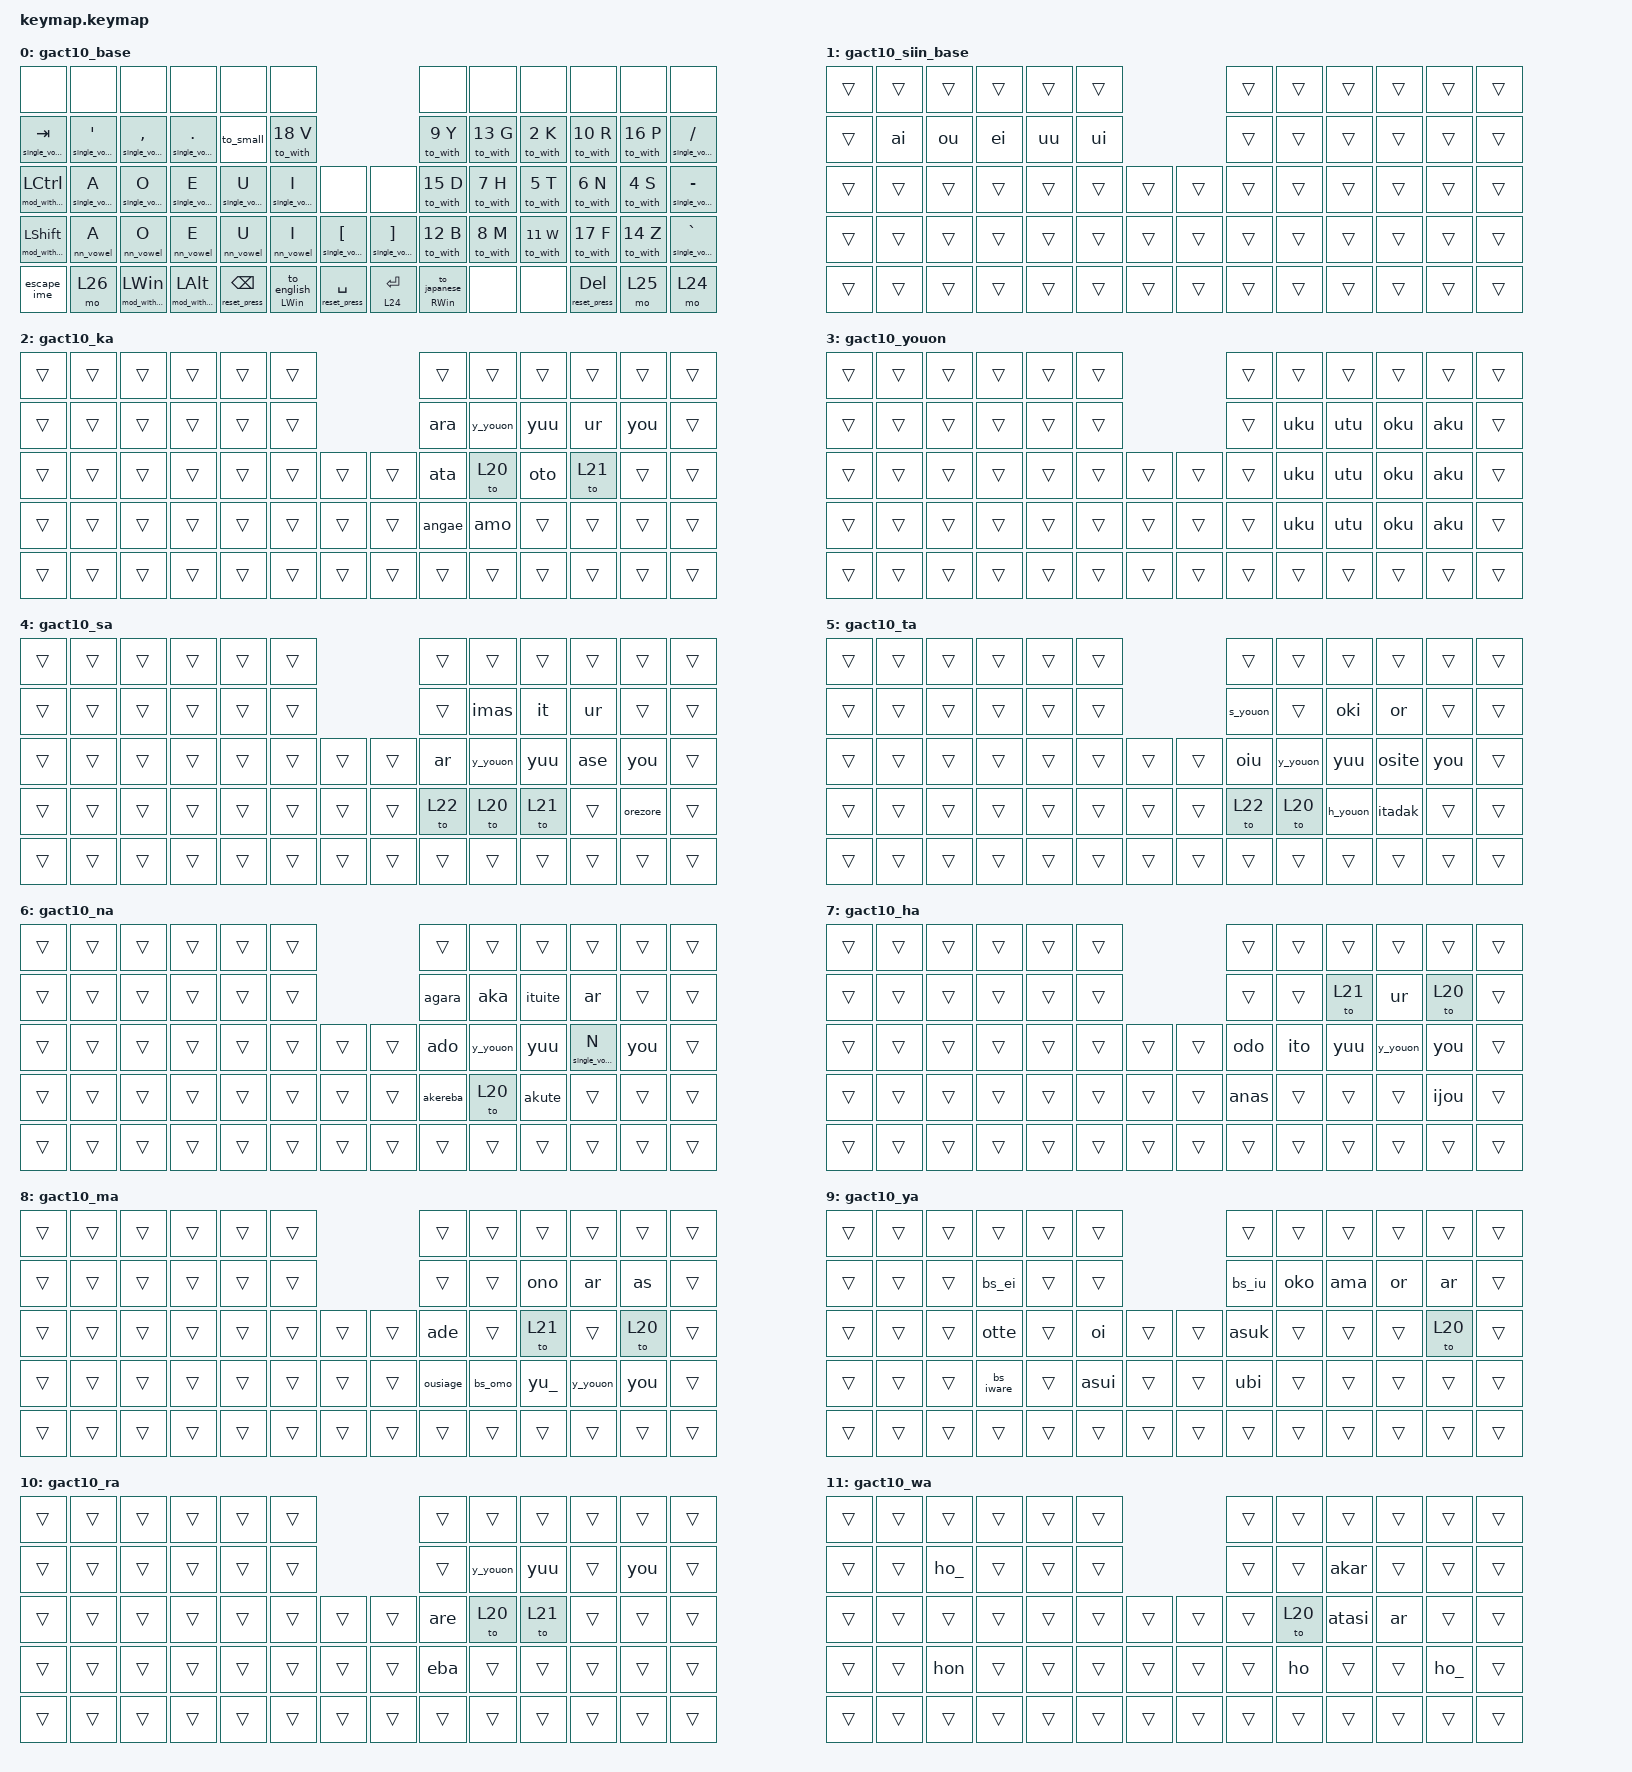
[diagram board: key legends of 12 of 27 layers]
#include <behaviors.dtsi>
#include <dt-bindings/zmk/bt.h>
#include <dt-bindings/zmk/keys.h>
#include <dt-bindings/zmk/outputs.h>
#include <dt-bindings/zmk/pointing.h>

/ {
    combos {
        compatible = "zmk,combos";

        lpar {
            bindings = <&kp LPAR>;
            key-positions = <28 16>;
        };

        rpar {
            bindings = <&kp RPAR>;
            key-positions = <17 29>;
        };
    };

    macros {
        to_small: small {
            compatible = "zmk,behavior-macro";
            #binding-cells = <0>;
            bindings = <&to 0 &tog 19 &kp X &kp T &kp U>;
            label = "SMALL";
            wait-ms = <0>;
            tap-ms = <0>;
        };

        ai: ai {
            compatible = "zmk,behavior-macro";
            #binding-cells = <0>;
            bindings = <&to 0 &kp A &kp I>;
            label = "AI";
            wait-ms = <0>;
            tap-ms = <0>;
        };

        ou: ou {
            compatible = "zmk,behavior-macro";
            #binding-cells = <0>;
            bindings = <&to 0 &kp O &kp U>;
            label = "OU";
            wait-ms = <0>;
            tap-ms = <0>;
        };

        ei: ei {
            compatible = "zmk,behavior-macro";
            #binding-cells = <0>;
            bindings = <&to 0 &kp E &kp I>;
            label = "EI";
            wait-ms = <0>;
            tap-ms = <0>;
        };

        uu: uu {
            compatible = "zmk,behavior-macro";
            #binding-cells = <0>;
            bindings = <&to 0 &kp U &kp U>;
            label = "UU";
            wait-ms = <0>;
            tap-ms = <0>;
        };

        ui: ui {
            compatible = "zmk,behavior-macro";
            #binding-cells = <0>;
            bindings = <&to 0 &kp U &kp I>;
            label = "UI";
            wait-ms = <0>;
            tap-ms = <0>;
        };

        ara: ara {
            compatible = "zmk,behavior-macro";
            #binding-cells = <0>;
            bindings = <&to 0 &kp A &kp R &kp A>;
            label = "ARA";
            wait-ms = <0>;
            tap-ms = <0>;
        };

        ata: ata {
            compatible = "zmk,behavior-macro";
            #binding-cells = <0>;
            bindings = <&to 0 &kp A &kp T &kp A>;
            label = "ATA";
            wait-ms = <0>;
            tap-ms = <0>;
        };

        angae: angae {
            compatible = "zmk,behavior-macro";
            #binding-cells = <0>;
            bindings = <&to 0 &kp A &kp N &kp G &kp A &kp E>;
            label = "ANGAE";
            wait-ms = <0>;
            tap-ms = <0>;
        };

        amo: amo {
            compatible = "zmk,behavior-macro";
            #binding-cells = <0>;
            bindings = <&to 0 &kp A &kp M &kp O>;
            label = "AMO";
            wait-ms = <0>;
            tap-ms = <0>;
        };

        y_youon: y_youon {
            compatible = "zmk,behavior-macro";
            #binding-cells = <0>;
            bindings = <&to 0 &tog 1 &tog 3 &kp Y>;
            label = "Y_YOUON";
            wait-ms = <0>;
            tap-ms = <0>;
        };

        oto: oto {
            compatible = "zmk,behavior-macro";
            #binding-cells = <0>;
            bindings = <&to 0 &kp O &kp T &kp O>;
            label = "OTO";
            wait-ms = <0>;
            tap-ms = <0>;
        };

        yuu: yuu {
            compatible = "zmk,behavior-macro";
            #binding-cells = <0>;
            bindings = <&to 0 &kp Y &kp U &kp U>;
            label = "YUU";
            wait-ms = <0>;
            tap-ms = <0>;
        };

        you: you {
            compatible = "zmk,behavior-macro";
            #binding-cells = <0>;
            bindings = <&to 0 &kp Y &kp O &kp U>;
            label = "YOU";
            wait-ms = <0>;
            tap-ms = <0>;
        };

        ur: ur {
            compatible = "zmk,behavior-macro";
            #binding-cells = <0>;
            bindings = <&to 0 &tog 1 &tog 10 &kp U &kp R>;
            label = "UR";
            wait-ms = <0>;
            tap-ms = <0>;
        };

        uku: uku {
            compatible = "zmk,behavior-macro";
            #binding-cells = <0>;
            bindings = <&to 0 &kp U &kp K &kp U>;
            label = "UKU";
            wait-ms = <0>;
            tap-ms = <0>;
        };

        utu: utu {
            compatible = "zmk,behavior-macro";
            #binding-cells = <0>;
            bindings = <&to 0 &kp U &kp T &kp U>;
            label = "UTU";
            wait-ms = <0>;
            tap-ms = <0>;
        };

        oku: otu {
            compatible = "zmk,behavior-macro";
            #binding-cells = <0>;
            bindings = <&to 0 &kp O &kp K &kp U>;
            label = "OTU";
            wait-ms = <0>;
            tap-ms = <0>;
        };

        aku: aku {
            compatible = "zmk,behavior-macro";
            #binding-cells = <0>;
            bindings = <&to 0 &kp A &kp K &kp U>;
            label = "AKU";
            wait-ms = <0>;
            tap-ms = <0>;
        };

        ar: ar {
            compatible = "zmk,behavior-macro";
            #binding-cells = <0>;
            bindings = <&to 0 &tog 1 &tog 10 &kp A &kp R>;
            label = "AR";
            wait-ms = <0>;
            tap-ms = <0>;
        };

        imas: imas {
            compatible = "zmk,behavior-macro";
            #binding-cells = <0>;
            bindings = <&to 0 &tog 1 &to 4 &kp I &kp M &kp A &kp S>;
            label = "IMAS";
            wait-ms = <0>;
            tap-ms = <0>;
        };

        it: it {
            compatible = "zmk,behavior-macro";
            #binding-cells = <0>;
            bindings = <&to 0 &tog 1 &tog 5 &kp I &kp T>;
            label = "IT";
            wait-ms = <0>;
            tap-ms = <0>;
        };

        orezore: orezore {
            compatible = "zmk,behavior-macro";
            #binding-cells = <0>;
            bindings = <&to 0 &kp O &kp R &kp E &kp Z &kp O &kp R &kp E>;
            label = "OREZORE";
            wait-ms = <0>;
            tap-ms = <0>;
        };

        ase: ase {
            compatible = "zmk,behavior-macro";
            #binding-cells = <0>;
            bindings = <&to 0 &kp A &kp S &kp E>;
            label = "ASE";
            wait-ms = <0>;
            tap-ms = <0>;
        };

        s_youon: s_youon {
            compatible = "zmk,behavior-macro";
            #binding-cells = <0>;
            bindings = <&to 0 &tog 1 &to 3 &kp S>;
            label = "S_YOUON";
            wait-ms = <0>;
            tap-ms = <0>;
        };

        oiu: oiu {
            compatible = "zmk,behavior-macro";
            #binding-cells = <0>;
            bindings = <&to 0 &kp O &kp I &kp U>;
            label = "OIU";
            wait-ms = <0>;
            tap-ms = <0>;
        };

        oki: oki {
            compatible = "zmk,behavior-macro";
            #binding-cells = <0>;
            bindings = <&to 0 &kp O &kp K &kp I>;
            label = "OKI";
            wait-ms = <0>;
            tap-ms = <0>;
        };

        osite: osite {
            compatible = "zmk,behavior-macro";
            #binding-cells = <0>;
            bindings = <&to 0 &kp O &kp S &kp I &kp T &kp E>;
            label = "OSITE";
            wait-ms = <0>;
            tap-ms = <0>;
        };

        or: or {
            compatible = "zmk,behavior-macro";
            #binding-cells = <0>;
            bindings = <&to 0 &tog 1 &tog 10 &kp O &kp R>;
            label = "OR";
            wait-ms = <0>;
            tap-ms = <0>;
        };

        itadak: itadak {
            compatible = "zmk,behavior-macro";
            #binding-cells = <0>;
            bindings = <&to 0 &tog 1 &tog 2 &kp BACKSPACE &kp I &kp T &kp A &kp D &kp A &kp K>;
            label = "ITADAK";
            wait-ms = <0>;
            tap-ms = <0>;
        };

        h_youon: h_youon {
            compatible = "zmk,behavior-macro";
            #binding-cells = <0>;
            bindings = <&to 0 &tog 1 &tog 3 &kp H>;
            label = "H_YOUON";
            wait-ms = <0>;
            tap-ms = <0>;
        };

        agara: agara {
            compatible = "zmk,behavior-macro";
            #binding-cells = <0>;
            bindings = <&to 0 &kp A &kp G &kp A &kp R &kp A>;
            label = "AGARA";
            wait-ms = <0>;
            tap-ms = <0>;
        };

        ado: ado {
            compatible = "zmk,behavior-macro";
            #binding-cells = <0>;
            bindings = <&to 0 &kp A &kp D &kp O>;
            label = "ADO";
            wait-ms = <0>;
            tap-ms = <0>;
        };

        akereba: akereba {
            compatible = "zmk,behavior-macro";
            #binding-cells = <0>;
            bindings = <&to 0 &kp A &kp K &kp E &kp R &kp E &kp B &kp A>;
            label = "AKEREBA";
            wait-ms = <0>;
            tap-ms = <0>;
        };

        aka: aka {
            compatible = "zmk,behavior-macro";
            #binding-cells = <0>;
            bindings = <&to 0 &kp A &kp K &kp A>;
            label = "AKA";
            wait-ms = <0>;
            tap-ms = <0>;
        };

        ituite: ituite {
            compatible = "zmk,behavior-macro";
            #binding-cells = <0>;
            bindings = <&to 0 &kp I &kp T &kp U &kp I &kp T &kp E>;
            label = "ITUITE";
            wait-ms = <0>;
            tap-ms = <0>;
        };

        akute: akute {
            compatible = "zmk,behavior-macro";
            #binding-cells = <0>;
            bindings = <&to 0 &kp A &kp K &kp U &kp T &kp E>;
            label = "AKUTE";
            wait-ms = <0>;
            tap-ms = <0>;
        };

        odo: odo {
            compatible = "zmk,behavior-macro";
            #binding-cells = <0>;
            bindings = <&to 0 &kp O &kp D &kp O>;
            label = "ODO";
            wait-ms = <0>;
            tap-ms = <0>;
        };

        anas: anas {
            compatible = "zmk,behavior-macro";
            #binding-cells = <0>;
            bindings = <&to 0 &tog 1 &tog 4 &kp A &kp N &kp A &kp S>;
            label = "ANAS";
            wait-ms = <0>;
            tap-ms = <0>;
        };

        ito: ito {
            compatible = "zmk,behavior-macro";
            #binding-cells = <0>;
            bindings = <&to 0 &kp I &kp T &kp O>;
            label = "ITO";
            wait-ms = <0>;
            tap-ms = <0>;
        };

        ijou: ijou {
            compatible = "zmk,behavior-macro";
            #binding-cells = <0>;
            bindings = <&to 0 &kp I &kp J &kp O &kp U>;
            label = "IJOU";
            wait-ms = <0>;
            tap-ms = <0>;
        };

        ade: ade {
            compatible = "zmk,behavior-macro";
            #binding-cells = <0>;
            bindings = <&to 0 &kp A &kp D &kp E>;
            label = "ADE";
            wait-ms = <0>;
            tap-ms = <0>;
        };

        ousiage: ousiage {
            compatible = "zmk,behavior-macro";
            #binding-cells = <0>;
            bindings = <&to 0 &kp O &kp U &kp S &kp I &kp A &kp G &kp E>;
            label = "OUSIAGE";
            wait-ms = <0>;
            tap-ms = <0>;
        };

        bs_omo: omo {
            compatible = "zmk,behavior-macro";
            #binding-cells = <0>;
            bindings = <&to 0 &kp BACKSPACE &kp O &kp M &kp O>;
            label = "OMO";
            wait-ms = <0>;
            tap-ms = <0>;
        };

        ono: ono {
            compatible = "zmk,behavior-macro";
            #binding-cells = <0>;
            bindings = <&to 0 &kp O &kp N &kp O>;
            label = "ONO";
            wait-ms = <0>;
            tap-ms = <0>;
        };

        yu_: yu_ {
            compatible = "zmk,behavior-macro";
            #binding-cells = <0>;
            bindings = <&to 0 &kp Y &kp U &kp MINUS>;
            label = "YU_";
            wait-ms = <0>;
            tap-ms = <0>;
        };

        as: as {
            compatible = "zmk,behavior-macro";
            #binding-cells = <0>;
            bindings = <&to 0 &tog 1 &tog 4 &kp A &kp S>;
            label = "AS";
            wait-ms = <0>;
            tap-ms = <0>;
        };

        otte: otte {
            compatible = "zmk,behavior-macro";
            #binding-cells = <0>;
            bindings = <&to 0 &kp O &kp T &kp T &kp E>;
            label = "OTTE";
            wait-ms = <0>;
            tap-ms = <0>;
        };

        bs_ei: bs_ei {
            compatible = "zmk,behavior-macro";
            #binding-cells = <0>;
            bindings = <&to 0 &kp BACKSPACE &kp E &kp I>;
            label = "BS_EI";
            wait-ms = <0>;
            tap-ms = <0>;
        };

        bs_iware: bs_iware {
            compatible = "zmk,behavior-macro";
            #binding-cells = <0>;
            bindings = <&to 0 &kp BACKSPACE &kp I &kp W &kp A &kp R &kp E>;
            label = "BS_IWARE";
            wait-ms = <0>;
            tap-ms = <0>;
        };

        oi: oi {
            compatible = "zmk,behavior-macro";
            #binding-cells = <0>;
            bindings = <&to 0 &kp O &kp I>;
            label = "OI";
            wait-ms = <0>;
            tap-ms = <0>;
        };

        asui: asui {
            compatible = "zmk,behavior-macro";
            #binding-cells = <0>;
            bindings = <&to 0 &kp A &kp S &kp U &kp I>;
            label = "ASUI";
            wait-ms = <0>;
            tap-ms = <0>;
        };

        bs_iu: bs_iu {
            compatible = "zmk,behavior-macro";
            #binding-cells = <0>;
            bindings = <&to 0 &kp BACKSPACE &kp I &kp U>;
            label = "BS_IU";
            wait-ms = <0>;
            tap-ms = <0>;
        };

        oko: oko {
            compatible = "zmk,behavior-macro";
            #binding-cells = <0>;
            bindings = <&to 0 &kp O &kp K &kp O>;
            label = "OKO";
            wait-ms = <0>;
            tap-ms = <0>;
        };

        ama: ama {
            compatible = "zmk,behavior-macro";
            #binding-cells = <0>;
            bindings = <&to 0 &kp A &kp M &kp A>;
            label = "AMA";
            wait-ms = <0>;
            tap-ms = <0>;
        };

        asuk: asuk {
            compatible = "zmk,behavior-macro";
            #binding-cells = <0>;
            bindings = <&to 0 &tog 1 &tog 2 &kp A &kp S &kp U &kp K>;
            label = "ASUK";
            wait-ms = <0>;
            tap-ms = <0>;
        };

        ubi: ubi {
            compatible = "zmk,behavior-macro";
            #binding-cells = <0>;
            bindings = <&to 0 &kp U &kp B &kp I>;
            label = "UBI";
            wait-ms = <0>;
            tap-ms = <0>;
        };

        are: are {
            compatible = "zmk,behavior-macro";
            #binding-cells = <0>;
            bindings = <&to 0 &kp A &kp R &kp E>;
            label = "ARE";
            wait-ms = <0>;
            tap-ms = <0>;
        };

        eba: eba {
            compatible = "zmk,behavior-macro";
            #binding-cells = <0>;
            bindings = <&to 0 &kp E &kp B &kp A>;
            label = "EBA";
            wait-ms = <0>;
            tap-ms = <0>;
        };

        ho_: ho_ {
            compatible = "zmk,behavior-macro";
            #binding-cells = <0>;
            bindings = <&to 0 &kp H &kp O &kp MINUS>;
            label = "HO_";
            wait-ms = <0>;
            tap-ms = <0>;
        };

        atasi: atasi {
            compatible = "zmk,behavior-macro";
            #binding-cells = <0>;
            bindings = <&to 0 &kp A &kp T &kp A &kp S &kp I>;
            label = "ATASI";
            wait-ms = <0>;
            tap-ms = <0>;
        };

        ho: ho {
            compatible = "zmk,behavior-macro";
            #binding-cells = <0>;
            bindings = <&to 0 &kp H &kp O>;
            label = "HO";
            wait-ms = <0>;
            tap-ms = <0>;
        };

        akar: akar {
            compatible = "zmk,behavior-macro";
            #binding-cells = <0>;
            bindings = <&to 0 &tog 1 &tog 10 &kp A &kp K &kp A &kp R>;
            label = "AKAR";
            wait-ms = <0>;
            tap-ms = <0>;
        };

        hon: hon {
            compatible = "zmk,behavior-macro";
            #binding-cells = <0>;
            bindings = <&to 0 &kp H &kp O &kp N &kp N>;
            label = "HON";
            wait-ms = <0>;
            tap-ms = <0>;
        };

        eki: eki {
            compatible = "zmk,behavior-macro";
            #binding-cells = <0>;
            bindings = <&to 0 &kp E &kp K &kp I>;
            label = "EKI";
            wait-ms = <0>;
            tap-ms = <0>;
        };

        aruwo: aruwo {
            compatible = "zmk,behavior-macro";
            #binding-cells = <0>;
            bindings = <&to 0 &kp A &kp R &kp U &kp W &kp O>;
            label = "ARUWO";
            wait-ms = <0>;
            tap-ms = <0>;
        };

        bs_node: ode {
            compatible = "zmk,behavior-macro";
            #binding-cells = <0>;
            bindings = <&to 0 &kp BACKSPACE &kp N &kp O &kp D &kp E>;
            label = "ODE";
            wait-ms = <0>;
            tap-ms = <0>;
        };

        aga: aga {
            compatible = "zmk,behavior-macro";
            #binding-cells = <0>;
            bindings = <&to 0 &kp A &kp G &kp A>;
            label = "AGA";
            wait-ms = <0>;
            tap-ms = <0>;
        };

        eha: eha {
            compatible = "zmk,behavior-macro";
            #binding-cells = <0>;
            bindings = <&to 0 &kp E &kp H &kp A>;
            label = "EHA";
            wait-ms = <0>;
            tap-ms = <0>;
        };

        emo: emo {
            compatible = "zmk,behavior-macro";
            #binding-cells = <0>;
            bindings = <&to 0 &kp E &kp M &kp O>;
            label = "EMO";
            wait-ms = <0>;
            tap-ms = <0>;
        };

        ear: ear {
            compatible = "zmk,behavior-macro";
            #binding-cells = <0>;
            bindings = <&to 0 &tog 1 &tog 10 &kp E &kp A &kp R>;
            label = "EAR";
            wait-ms = <0>;
            tap-ms = <0>;
        };

        es: es {
            compatible = "zmk,behavior-macro";
            #binding-cells = <0>;
            bindings = <&to 0 &tog 1 &tog 4 &kp E &kp S>;
            label = "ES";
            wait-ms = <0>;
            tap-ms = <0>;
        };

        o_: o_ {
            compatible = "zmk,behavior-macro";
            #binding-cells = <0>;
            bindings = <&to 0 &kp O &kp MINUS>;
            label = "O_";
            wait-ms = <0>;
            tap-ms = <0>;
        };

        bs_onazi: bs_onazi {
            compatible = "zmk,behavior-macro";
            #binding-cells = <0>;
            bindings = <&to 0 &kp BACKSPACE &kp O &kp N &kp A &kp Z &kp I>;
            label = "BS_ONAZI";
            wait-ms = <0>;
            tap-ms = <0>;
        };

        yun: yun {
            compatible = "zmk,behavior-macro";
            #binding-cells = <0>;
            bindings = <&to 0 &kp Y &kp U &kp N &kp N>;
            label = "YUN";
            wait-ms = <0>;
            tap-ms = <0>;
        };

        yu: yu {
            compatible = "zmk,behavior-macro";
            #binding-cells = <0>;
            bindings = <&to 0 &kp Y &kp U>;
            label = "YU";
            wait-ms = <0>;
            tap-ms = <0>;
        };

        x_txx: ta {
            compatible = "zmk,behavior-macro-one-param";
            #binding-cells = <1>;
            bindings = <&to 0 &kp T &macro_param_1to1 &kp MACRO_PLACEHOLDER>;
            label = "TA";
            wait-ms = <0>;
            tap-ms = <0>;
        };

        bs_x_xx: bs_xa {
            compatible = "zmk,behavior-macro-one-param";
            #binding-cells = <1>;
            bindings = <&to 0 &kp BACKSPACE &kp X &macro_param_1to1 &kp MACRO_PLACEHOLDER>;
            label = "BS_XA";
            wait-ms = <0>;
            tap-ms = <0>;
        };

        bs_xwa: bs_xwa {
            compatible = "zmk,behavior-macro";
            #binding-cells = <0>;
            bindings = <&to 0 &kp BACKSPACE &kp X &kp W &kp A>;
            label = "BS_XWA";
            wait-ms = <0>;
            tap-ms = <0>;
        };

        bs_xy: bs_xy {
            compatible = "zmk,behavior-macro";
            #binding-cells = <0>;
            bindings = <&to 0 &to 1 &kp BACKSPACE &kp X &kp Y>;
            label = "BS_XY";
            wait-ms = <0>;
            tap-ms = <0>;
        };

        to_with: to_sa {
            compatible = "zmk,behavior-macro-two-param";
            #binding-cells = <2>;
            bindings = <&to 0 &tog 1 &macro_param_1to1 &tog MACRO_PLACEHOLDER &macro_param_2to1 &kp MACRO_PLACEHOLDER>;
            label = "TO_SA";
            wait-ms = <0>;
            tap-ms = <0>;
        };

        to_japanese: to_japanese {
            compatible = "zmk,behavior-macro";
            #binding-cells = <0>;
            bindings = <&to 0 &kp LANGUAGE_1>;
            label = "TO_JAPANESE";
            wait-ms = <0>;
            tap-ms = <0>;
        };

        to_english: to_english {
            compatible = "zmk,behavior-macro";
            #binding-cells = <0>;
            bindings = <&to 23 &kp LANGUAGE_2>;
            label = "TO_ENGLISH";
            wait-ms = <0>;
            tap-ms = <0>;
        };

        xx_ku: xx_ku {
            compatible = "zmk,behavior-macro-one-param";
            #binding-cells = <1>;
            bindings = <&to 0 &macro_param_1to1 &kp MACRO_PLACEHOLDER &kp K &kp U>;
            label = "XX_KU";
            wait-ms = <0>;
            tap-ms = <0>;
        };

        xx_ki: xx_ki {
            compatible = "zmk,behavior-macro-one-param";
            #binding-cells = <1>;
            bindings = <&to 0 &macro_param_1to1 &kp MACRO_PLACEHOLDER &kp K &kp I>;
            label = "XX_KI";
            wait-ms = <0>;
            tap-ms = <0>;
        };

        xx_tu: xx_tu {
            compatible = "zmk,behavior-macro-one-param";
            #binding-cells = <1>;
            bindings = <&to 0 &macro_param_1to1 &kp MACRO_PLACEHOLDER &kp T &kp U>;
            label = "XX_TU";
            wait-ms = <0>;
            tap-ms = <0>;
        };

        single_vowel: single_vowel {
            compatible = "zmk,behavior-macro-one-param";
            #binding-cells = <1>;
            bindings = <&to 0 &macro_param_1to1 &kp MACRO_PLACEHOLDER>;
            label = "SINGLE_VOWEL";
            wait-ms = <0>;
            tap-ms = <0>;
        };

        nn_vowel: nn_vowel {
            compatible = "zmk,behavior-macro-one-param";
            #binding-cells = <1>;
            bindings = <&to 0 &macro_param_1to1 &kp MACRO_PLACEHOLDER &kp N &kp N>;
            label = "NN_VOWEL";
            wait-ms = <0>;
            tap-ms = <0>;
        };

        escape_ime: escape_ime {
            compatible = "zmk,behavior-macro";
            #binding-cells = <0>;
            bindings = <&kp ESCAPE &kp LANGUAGE_2 &to 23>;
            label = "ESCAPE_IME";
            wait-ms = <0>;
            tap-ms = <0>;
        };

        mod_with_mo: new_macro {
            compatible = "zmk,behavior-macro-one-param";
            #binding-cells = <1>;
            bindings =
                <&macro_press>,
                <&mo 23 &macro_param_1to1 &kp MACRO_PLACEHOLDER>,
                <&macro_pause_for_release>,
                <&macro_release>,
                <&mo 23 &macro_param_1to1 &kp MACRO_PLACEHOLDER>;

            label = "NEW_MACRO";
        };

        reset_press: reset_press {
            compatible = "zmk,behavior-macro-one-param";
            #binding-cells = <1>;
            bindings =
                <&to 0>,
                <&macro_press>,
                <&macro_param_1to1 &kp MACRO_PLACEHOLDER>,
                <&macro_pause_for_release>,
                <&macro_release>,
                <&macro_param_1to1 &kp MACRO_PLACEHOLDER>;

            label = "RESET_PRESS";
        };
    };

    behaviors {
        hold_and_tap_eng: hold_and_tap_eng {
            compatible = "zmk,behavior-hold-tap";
            label = "HOLD_AND_TAP_ENG";
            bindings = <&kp>, <&to_english>;

            #binding-cells = <2>;
            tapping-term-ms = <200>;
        };

        hold_and_tap_ja: hold_and_tap_ja {
            compatible = "zmk,behavior-hold-tap";
            label = "HOLD_AND_TAP_JA";
            bindings = <&kp>, <&to_japanese>;

            #binding-cells = <2>;
            tapping-term-ms = <200>;
        };

        ht_vowel: ht_vowel {
            compatible = "zmk,behavior-hold-tap";
            label = "HT_VOWEL";
            bindings = <&mo>, <&single_vowel>;

            #binding-cells = <2>;
            tapping-term-ms = <200>;
        };
    };

    keymap {
        compatible = "zmk,keymap";

        gact10_base {
            bindings = <
&none                    &none              &none                &none                  &none                   &none                                                                              &none                    &none          &none          &none                &none          &none
&single_vowel TAB        &single_vowel SQT  &single_vowel COMMA  &single_vowel PERIOD   &to_small               &to_with 18 V                                                                      &to_with 9 Y             &to_with 13 G  &to_with 2 K   &to_with 10 R        &to_with 16 P  &single_vowel SLASH
&mod_with_mo LCTRL       &single_vowel A    &single_vowel O      &single_vowel E        &single_vowel U         &single_vowel I           &none                       &none                        &to_with 15 D            &to_with 7 H   &to_with 5 T   &to_with 6 N         &to_with 4 S   &single_vowel MINUS
&mod_with_mo LEFT_SHIFT  &nn_vowel A        &nn_vowel O          &nn_vowel E            &nn_vowel U             &nn_vowel I               &single_vowel LEFT_BRACKET  &single_vowel RIGHT_BRACKET  &to_with 12 B            &to_with 8 M   &to_with 11 W  &to_with 17 F        &to_with 14 Z  &single_vowel GRAVE
&escape_ime              &mo 26             &mod_with_mo LWIN    &mod_with_mo LEFT_ALT  &reset_press BACKSPACE  &hold_and_tap_eng LWIN 0  &reset_press SPACE          &ht_vowel 24 ENTER           &hold_and_tap_ja RWIN 0  &none          &none          &reset_press DELETE  &mo 25         &mo 24
            >;
        };

        gact10_siin_base {
            bindings = <
&trans  &trans  &trans  &trans  &trans  &trans                  &trans  &trans  &trans  &trans  &trans  &trans
&trans  &ai     &ou     &ei     &uu     &ui                     &trans  &trans  &trans  &trans  &trans  &trans
&trans  &trans  &trans  &trans  &trans  &trans  &trans  &trans  &trans  &trans  &trans  &trans  &trans  &trans
&trans  &trans  &trans  &trans  &trans  &trans  &trans  &trans  &trans  &trans  &trans  &trans  &trans  &trans
&trans  &trans  &trans  &trans  &trans  &trans  &trans  &trans  &trans  &trans  &trans  &trans  &trans  &trans
            >;
        };

        gact10_ka {
            bindings = <
&trans  &trans  &trans  &trans  &trans  &trans                  &trans  &trans    &trans  &trans  &trans  &trans
&trans  &trans  &trans  &trans  &trans  &trans                  &ara    &y_youon  &yuu    &ur     &you    &trans
&trans  &trans  &trans  &trans  &trans  &trans  &trans  &trans  &ata    &to 20    &oto    &to 21  &trans  &trans
&trans  &trans  &trans  &trans  &trans  &trans  &trans  &trans  &angae  &amo      &trans  &trans  &trans  &trans
&trans  &trans  &trans  &trans  &trans  &trans  &trans  &trans  &trans  &trans    &trans  &trans  &trans  &trans
            >;
        };

        gact10_youon {
            bindings = <
&trans  &trans  &trans  &trans  &trans  &trans                  &trans  &trans  &trans  &trans  &trans  &trans
&trans  &trans  &trans  &trans  &trans  &trans                  &trans  &uku    &utu    &oku    &aku    &trans
&trans  &trans  &trans  &trans  &trans  &trans  &trans  &trans  &trans  &uku    &utu    &oku    &aku    &trans
&trans  &trans  &trans  &trans  &trans  &trans  &trans  &trans  &trans  &uku    &utu    &oku    &aku    &trans
&trans  &trans  &trans  &trans  &trans  &trans  &trans  &trans  &trans  &trans  &trans  &trans  &trans  &trans
            >;
        };

        gact10_sa {
            bindings = <
&trans  &trans  &trans  &trans  &trans  &trans                  &trans  &trans    &trans  &trans  &trans    &trans
&trans  &trans  &trans  &trans  &trans  &trans                  &trans  &imas     &it     &ur     &trans    &trans
&trans  &trans  &trans  &trans  &trans  &trans  &trans  &trans  &ar     &y_youon  &yuu    &ase    &you      &trans
&trans  &trans  &trans  &trans  &trans  &trans  &trans  &trans  &to 22  &to 20    &to 21  &trans  &orezore  &trans
&trans  &trans  &trans  &trans  &trans  &trans  &trans  &trans  &trans  &trans    &trans  &trans  &trans    &trans
            >;
        };

        gact10_ta {
            bindings = <
&trans  &trans  &trans  &trans  &trans  &trans                  &trans    &trans    &trans    &trans   &trans  &trans
&trans  &trans  &trans  &trans  &trans  &trans                  &s_youon  &trans    &oki      &or      &trans  &trans
&trans  &trans  &trans  &trans  &trans  &trans  &trans  &trans  &oiu      &y_youon  &yuu      &osite   &you    &trans
&trans  &trans  &trans  &trans  &trans  &trans  &trans  &trans  &to 22    &to 20    &h_youon  &itadak  &trans  &trans
&trans  &trans  &trans  &trans  &trans  &trans  &trans  &trans  &trans    &trans    &trans    &trans   &trans  &trans
            >;
        };

        gact10_na {
            bindings = <
&trans  &trans  &trans  &trans  &trans  &trans                  &trans    &trans    &trans   &trans           &trans  &trans
&trans  &trans  &trans  &trans  &trans  &trans                  &agara    &aka      &ituite  &ar              &trans  &trans
&trans  &trans  &trans  &trans  &trans  &trans  &trans  &trans  &ado      &y_youon  &yuu     &single_vowel N  &you    &trans
&trans  &trans  &trans  &trans  &trans  &trans  &trans  &trans  &akereba  &to 20    &akute   &trans           &trans  &trans
&trans  &trans  &trans  &trans  &trans  &trans  &trans  &trans  &trans    &trans    &trans   &trans           &trans  &trans
            >;
        };

        gact10_ha {
            bindings = <
&trans  &trans  &trans  &trans  &trans  &trans                  &trans  &trans  &trans  &trans    &trans  &trans
&trans  &trans  &trans  &trans  &trans  &trans                  &trans  &trans  &to 21  &ur       &to 20  &trans
&trans  &trans  &trans  &trans  &trans  &trans  &trans  &trans  &odo    &ito    &yuu    &y_youon  &you    &trans
&trans  &trans  &trans  &trans  &trans  &trans  &trans  &trans  &anas   &trans  &trans  &trans    &ijou   &trans
&trans  &trans  &trans  &trans  &trans  &trans  &trans  &trans  &trans  &trans  &trans  &trans    &trans  &trans
            >;
        };

        gact10_ma {
            bindings = <
&trans  &trans  &trans  &trans  &trans  &trans                  &trans    &trans   &trans  &trans    &trans  &trans
&trans  &trans  &trans  &trans  &trans  &trans                  &trans    &trans   &ono    &ar       &as     &trans
&trans  &trans  &trans  &trans  &trans  &trans  &trans  &trans  &ade      &trans   &to 21  &trans    &to 20  &trans
&trans  &trans  &trans  &trans  &trans  &trans  &trans  &trans  &ousiage  &bs_omo  &yu_    &y_youon  &you    &trans
&trans  &trans  &trans  &trans  &trans  &trans  &trans  &trans  &trans    &trans   &trans  &trans    &trans  &trans
            >;
        };

        gact10_ya {
            bindings = <
&trans  &trans  &trans  &trans     &trans  &trans                  &trans  &trans  &trans  &trans  &trans  &trans
&trans  &trans  &trans  &bs_ei     &trans  &trans                  &bs_iu  &oko    &ama    &or     &ar     &trans
&trans  &trans  &trans  &otte      &trans  &oi     &trans  &trans  &asuk   &trans  &trans  &trans  &to 20  &trans
&trans  &trans  &trans  &bs_iware  &trans  &asui   &trans  &trans  &ubi    &trans  &trans  &trans  &trans  &trans
&trans  &trans  &trans  &trans     &trans  &trans  &trans  &trans  &trans  &trans  &trans  &trans  &trans  &trans
            >;
        };

        gact10_ra {
            bindings = <
&trans  &trans  &trans  &trans  &trans  &trans                  &trans  &trans    &trans  &trans  &trans  &trans
&trans  &trans  &trans  &trans  &trans  &trans                  &trans  &y_youon  &yuu    &trans  &you    &trans
&trans  &trans  &trans  &trans  &trans  &trans  &trans  &trans  &are    &to 20    &to 21  &trans  &trans  &trans
&trans  &trans  &trans  &trans  &trans  &trans  &trans  &trans  &eba    &trans    &trans  &trans  &trans  &trans
&trans  &trans  &trans  &trans  &trans  &trans  &trans  &trans  &trans  &trans    &trans  &trans  &trans  &trans
            >;
        };

        gact10_wa {
            bindings = <
&trans  &trans  &trans  &trans  &trans  &trans                  &trans  &trans  &trans  &trans  &trans  &trans
&trans  &trans  &ho_    &trans  &trans  &trans                  &trans  &trans  &akar   &trans  &trans  &trans
&trans  &trans  &trans  &trans  &trans  &trans  &trans  &trans  &trans  &to 20  &atasi  &ar     &trans  &trans
&trans  &trans  &hon    &trans  &trans  &trans  &trans  &trans  &trans  &ho     &trans  &trans  &ho_    &trans
&trans  &trans  &trans  &trans  &trans  &trans  &trans  &trans  &trans  &trans  &trans  &trans  &trans  &trans
            >;
        };

        gact10_ba {
            bindings = <
&trans  &trans  &trans  &trans  &trans  &trans                  &trans  &trans  &trans  &trans    &trans  &trans
&trans  &trans  &trans  &trans  &trans  &trans                  &trans  &trans  &eki    &ur       &ar     &trans
&trans  &trans  &trans  &trans  &trans  &trans  &trans  &trans  &trans  &trans  &to 21  &trans    &to 20  &trans
&trans  &trans  &trans  &trans  &trans  &trans  &trans  &trans  &trans  &trans  &yuu    &y_youon  &you    &trans
&trans  &trans  &trans  &trans  &trans  &trans  &trans  &trans  &trans  &trans  &trans  &trans    &trans  &trans
            >;
        };

        gact10_ga {
            bindings = <
&trans  &trans  &trans  &trans  &trans  &trans                  &trans  &trans  &trans  &trans    &trans  &trans
&trans  &trans  &trans  &trans  &trans  &trans                  &trans  &ur     &yuu    &y_youon  &you    &trans
&trans  &trans  &trans  &trans  &trans  &trans  &trans  &trans  &trans  &trans  &oto    &trans    &to 20  &trans
&trans  &trans  &trans  &trans  &trans  &trans  &trans  &trans  &trans  &trans  &trans  &trans    &trans  &trans
&trans  &trans  &trans  &trans  &trans  &trans  &trans  &trans  &trans  &trans  &trans  &trans    &trans  &trans
            >;
        };

        gact10_za {
            bindings = <
&trans  &trans  &trans  &trans  &trans  &trans                  &trans  &trans    &trans  &trans  &trans  &trans
&trans  &trans  &trans  &trans  &trans  &trans                  &trans  &trans    &trans  &trans  &trans  &trans
&trans  &trans  &trans  &trans  &trans  &trans  &trans  &trans  &to 22  &to 20    &to 21  &ur     &trans  &trans
&trans  &trans  &trans  &trans  &trans  &trans  &trans  &trans  &aruwo  &y_youon  &yuu    &ar     &you    &trans
&trans  &trans  &trans  &trans  &trans  &trans  &trans  &trans  &trans  &trans    &trans  &trans  &trans  &trans
            >;
        };

        gact10_da {
            bindings = <
&trans  &trans  &trans  &trans  &trans  &trans                  &trans    &trans  &trans  &trans    &trans  &trans
&trans  &trans  &trans  &trans  &trans  &trans                  &trans    &aga    &eki    &or       &to 20  &trans
&trans  &trans  &trans  &trans  &trans  &trans  &trans  &trans  &bs_node  &eha    &ear    &y_youon  &es     &trans
&trans  &trans  &trans  &trans  &trans  &trans  &trans  &trans  &h_youon  &emo    &trans  &trans    &trans  &trans
&trans  &trans  &trans  &trans  &trans  &trans  &trans  &trans  &trans    &trans  &trans  &trans    &trans  &trans
            >;
        };

        gact10_pa {
            bindings = <
&trans  &trans  &trans  &trans  &trans  &trans                  &trans  &trans    &trans  &trans  &trans  &trans
&trans  &trans  &trans  &trans  &trans  &trans                  &trans  &y_youon  &yuu    &ur     &you    &trans
&trans  &trans  &trans  &trans  &trans  &trans  &trans  &trans  &trans  &to 20    &to 21  &trans  &trans  &trans
&trans  &trans  &trans  &trans  &trans  &trans  &trans  &trans  &trans  &trans    &trans  &trans  &trans  &trans
&trans  &trans  &trans  &trans  &trans  &trans  &trans  &trans  &trans  &trans    &trans  &trans  &trans  &trans
            >;
        };

        gact10_fa {
            bindings = <
&trans  &trans  &trans  &trans  &trans  &trans                  &trans  &trans  &trans  &trans     &trans  &trans
&trans  &trans  &o_     &trans  &yu_    &trans                  &trans  &trans  &trans  &trans     &trans  &trans
&trans  &trans  &trans  &trans  &yu     &trans  &trans  &trans  &trans  &to 20  &trans  &trans     &trans  &trans
&trans  &trans  &trans  &trans  &yun    &trans  &trans  &trans  &trans  &trans  &trans  &bs_onazi  &trans  &trans
&trans  &trans  &trans  &trans  &trans  &trans  &trans  &trans  &trans  &trans  &trans  &trans     &trans  &trans
            >;
        };

        gact10_va {
            bindings = <
&trans  &trans  &trans  &trans  &trans  &trans                  &trans  &trans  &trans  &trans  &trans  &trans
&trans  &trans  &o_     &trans  &yu_    &trans                  &trans  &trans  &trans  &trans  &trans  &trans
&trans  &trans  &trans  &trans  &yu     &trans  &trans  &trans  &trans  &trans  &trans  &trans  &trans  &trans
&trans  &trans  &trans  &trans  &yun    &trans  &trans  &trans  &trans  &trans  &trans  &trans  &trans  &trans
&trans  &trans  &trans  &trans  &trans  &trans  &trans  &trans  &trans  &trans  &trans  &trans  &trans  &trans
            >;
        };

        gact10_small {
            bindings = <
&trans  &trans      &trans      &trans      &trans      &trans                      &trans  &trans  &trans   &trans  &trans  &trans
&trans  &x_txx A    &x_txx O    &x_txx E    &x_txx U    &x_txx I                    &bs_xy  &trans  &trans   &trans  &trans  &trans
&trans  &bs_x_xx A  &bs_x_xx O  &bs_x_xx E  &bs_x_xx U  &bs_x_xx I  &trans  &trans  &trans  &trans  &trans   &trans  &trans  &trans
&trans  &trans      &trans      &trans      &trans      &trans      &trans  &trans  &trans  &trans  &bs_xwa  &trans  &trans  &trans
&trans  &trans      &trans      &trans      &trans      &trans      &trans  &trans  &trans  &trans  &trans   &trans  &trans  &trans
            >;
        };

        gact10_ku_youon {
            bindings = <
&trans  &trans    &trans    &trans    &trans    &trans                    &trans  &trans  &trans  &trans  &trans  &trans
&trans  &trans    &trans    &trans    &trans    &trans                    &trans  &trans  &trans  &trans  &trans  &trans
&trans  &xx_ku A  &xx_ku O  &xx_ku E  &xx_ku U  &xx_ku I  &trans  &trans  &trans  &trans  &trans  &trans  &trans  &trans
&trans  &trans    &trans    &trans    &trans    &trans    &trans  &trans  &trans  &trans  &trans  &trans  &trans  &trans
&trans  &trans    &trans    &trans    &trans    &trans    &trans  &trans  &trans  &trans  &trans  &trans  &trans  &trans
            >;
        };

        gact10_tu_youon {
            bindings = <
&trans  &trans    &trans    &trans    &trans    &trans                    &trans  &trans  &trans  &trans  &trans  &trans
&trans  &trans    &trans    &trans    &trans    &trans                    &trans  &trans  &trans  &trans  &trans  &trans
&trans  &xx_tu A  &xx_tu O  &xx_tu E  &xx_tu U  &xx_tu I  &trans  &trans  &trans  &trans  &trans  &trans  &trans  &trans
&trans  &trans    &trans    &trans    &trans    &trans    &trans  &trans  &trans  &trans  &trans  &trans  &trans  &trans
&trans  &trans    &trans    &trans    &trans    &trans    &trans  &trans  &trans  &trans  &trans  &trans  &trans  &trans
            >;
        };

        gact10_ki_youon {
            bindings = <
&trans  &trans    &trans    &trans    &trans    &trans                    &trans  &trans  &trans  &trans  &trans  &trans
&trans  &trans    &trans    &trans    &trans    &trans                    &trans  &trans  &trans  &trans  &trans  &trans
&trans  &xx_ki A  &xx_ki O  &xx_ki E  &xx_ki U  &xx_ki I  &trans  &trans  &trans  &trans  &trans  &trans  &trans  &trans
&trans  &trans    &trans    &trans    &trans    &trans    &trans  &trans  &trans  &trans  &trans  &trans  &trans  &trans
&trans  &trans    &trans    &trans    &trans    &trans    &trans  &trans  &trans  &trans  &trans  &trans  &trans  &trans
            >;
        };

        ascii {
            bindings = <
&none             &none          &none      &none         &none     &none                                        &none   &none  &none  &none       &none   &none
&kp TAB           &kp SQT        &kp COMMA  &kp PERIOD    &kp P     &kp Y                                        &kp F   &kp G  &kp C  &kp R       &kp L   &kp SLASH
&kp LEFT_CONTROL  &kp A          &kp O      &kp E         &kp U     &kp I   &none             &none              &kp D   &kp H  &kp T  &kp N       &kp S   &kp MINUS
&kp LSHFT         &kp SEMICOLON  &kp Q      &kp J         &kp K     &kp X   &kp LEFT_BRACKET  &kp RIGHT_BRACKET  &kp B   &kp M  &kp W  &kp V       &kp Z   &kp GRAVE
&escape_ime       &trans         &kp LGUI   &kp LEFT_ALT  &kp BSPC  &trans  &kp SPACE         &lt 24 ENTER       &trans  &none  &none  &kp DELETE  &trans  &trans
            >;
        };

        num_and_symbol {
            bindings = <
&trans  &trans       &trans        &trans        &trans        &trans                     &trans           &trans        &trans        &trans         &trans      &trans
&trans  &kp SLASH    &kp N7        &kp N8        &kp N9        &kp MINUS                  &kp EXCLAMATION  &kp UP_ARROW  &kp QUESTION  &kp AT         &kp CARET   &kp AMPS
&trans  &kp ASTRK    &kp NUMBER_4  &kp N5        &kp NUMBER_6  &kp PLUS   &trans  &trans  &kp LEFT         &kp DOWN      &kp RIGHT     &kp LESS_THAN  &kp DOLLAR  &kp GREATER_THAN
&trans  &kp HASH     &kp NUMBER_1  &kp NUMBER_2  &kp NUMBER_3  &kp EQUAL  &trans  &trans  &kp SLASH        &kp PIPE      &kp BSLH      &kp MINUS      &kp EQUAL   &kp PLUS
&trans  &kp PERCENT  &kp N0        &kp DOT       &trans        &trans     &trans  &trans  &trans           &trans        &trans        &trans         &trans      &trans
            >;
        };

        func_and_control {
            bindings = <
&trans  &trans   &trans   &trans        &trans        &trans                      &trans        &trans        &trans         &trans          &trans      &trans
&trans  &kp F1   &kp F2   &kp F3        &kp F4        &kp F5                      &kp HOME      &kp PG_UP     &kp PAGE_DOWN  &kp END         &kp ESCAPE  &trans
&trans  &kp F6   &kp F7   &kp F8        &kp F9        &kp F10     &trans  &trans  &kp LEFT      &kp DOWN      &kp UP_ARROW   &kp RIGHT       &kp TAB     &trans
&trans  &kp F11  &kp F12  &out OUT_USB  &out OUT_BLE  &bt BT_NXT  &trans  &trans  &bt BT_SEL 1  &bt BT_SEL 2  &bt BT_SEL 3   &bt BT_SEL 4    &kp PIPE    &trans
&trans  &trans   &trans   &trans        &trans        &trans      &trans  &trans  &trans        &trans        &trans         &bt BT_CLR_ALL  &trans      &trans
            >;
        };

        layer_1 {
            bindings = <
&trans  &trans  &trans  &trans     &trans     &trans                  &trans  &trans     &trans     &trans  &trans  &trans
&trans  &trans  &trans  &trans     &trans     &trans                  &trans  &trans     &trans     &trans  &trans  &trans
&trans  &trans  &trans  &mkp RCLK  &mkp LCLK  &trans  &trans  &trans  &trans  &mkp LCLK  &mkp RCLK  &trans  &trans  &trans
&trans  &trans  &trans  &trans     &trans     &trans  &trans  &trans  &trans  &trans     &trans     &trans  &trans  &trans
&trans  &trans  &trans  &trans     &trans     &trans  &trans  &trans  &trans  &trans     &trans     &trans  &trans  &trans
            >;
        };
    };

    conditional_layers { compatible = "zmk,conditional-layers"; };
};
